# ATmega16A device description
Architecture: AVR8; Family: megaAVR
Registers are 8-bit, access not given, no defined reset value unless marked. A register's access mark holds for its fields unless they carry their own. Offsets are from the block's base; [hi:lo] are bit positions; 'fields as' and 'values as' point back to an identical list.

## LOCKBIT — Lockbits
Instances: LOCKBIT 0 in lockbits
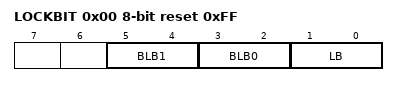
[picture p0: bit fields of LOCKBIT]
0x00 LOCKBIT reset 0xFF
  [5:4] BLB1 — Boot Loader Protection Mode
    0=LPM_SPM_DISABLE (LPM and SPM prohibited in Boot Section); 1=LPM_DISABLE (LPM prohibited in Boot Section); 2=SPM_DISABLE (SPM prohibited in Boot Section); 3=NO_LOCK (No lock on SPM and LPM in Boot Section)
  [3:2] BLB0 — Boot Loader Protection Mode
    0=LPM_SPM_DISABLE (LPM and SPM prohibited in Application Section); 1=LPM_DISABLE (LPM prohibited in Application Section); 2=SPM_DISABLE (SPM prohibited in Application Section); 3=NO_LOCK (No lock on SPM and LPM in Application Section)
  [1:0] LB — Memory Lock
    0=PROG_VER_DISABLED (Further programming and verification disabled); 2=PROG_DISABLED (Further programming disabled); 3=NO_LOCK (No memory lock features enabled)

## TC0 (TC8 module) — Timer/Counter, 8-bit
Instances: TC0 0x00
0x50 SFIOR — Special Function IO Register
  [0] PSR10 — Prescaler Reset Timer/Counter1 and Timer/Counter0
0x52 TCNT0 — Timer/Counter 0 Register
  [7:0] TCNT0 — Timer/Counter 0 bits
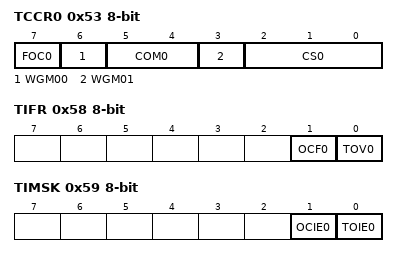
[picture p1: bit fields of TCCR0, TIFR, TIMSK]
0x53 TCCR0 — Timer/Counter Control Register
  [7] FOC0 — Force Output Compare
  [6] WGM00 — Waveform Generation Mode 0
    0=Normal; 2=PWM, Phase Correct; 1=CTC; 3=Fast PWM
  [5:4] COM0 — Compare Match Output Modes
  [3] WGM01 — Waveform Generation Mode 1
  [2:0] CS0 — Clock Selects
    0=No Clock Source (Stopped); 1=Running, No Prescaling; 2=Running, CLK/8; 3=Running, CLK/64; 4=Running, CLK/256; 5=Running, CLK/1024; 6=Running, ExtClk Tx Falling Edge; 7=Running, ExtClk Tx Rising Edge
0x58 TIFR — Timer/Counter Interrupt Flag register
  [1] OCF0 — Output Compare Flag 0
  [0] TOV0 — Timer/Counter0 Overflow Flag
0x59 TIMSK — Timer/Counter Interrupt Mask Register
  [1] OCIE0 — Timer/Counter0 Output Compare Match Interrupt register
  [0] TOIE0 — Timer/Counter0 Overflow Interrupt Enable
0x5C OCR0 — Output Compare 0 Register
  [7:0] OCR0 — Output Compare bits

## TC1 (TC16 module) — Timer/Counter, 16-bit
Instances: TC1 0x00
0x46 ICR1 16-bit — Timer/Counter1 Input Capture Register Bytes
  [15:0] ICR1 — Timer/Counter1 Input Capture bits
0x48 OCR1B 16-bit — Timer/Counter1 Output Compare Register Bytes
  [15:0] OCR1B — Timer/Counter1 Output Compare B bits
0x4A OCR1A 16-bit — Timer/Counter1 Output Compare Register Bytes
  [15:0] OCR1A — Timer/Counter1 Output Compare A bits
0x4C TCNT1 16-bit — Timer/Counter1 Bytes
  [15:0] TCNT1 — Timer/Counter1 bits
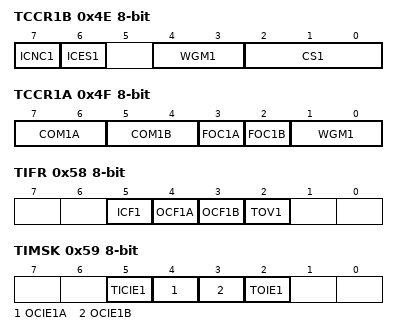
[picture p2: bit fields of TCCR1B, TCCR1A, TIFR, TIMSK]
0x4E TCCR1B — Timer/Counter1 Control Register B
  [7] ICNC1 — Input Capture 1 Noise Canceler
  [6] ICES1 — Input Capture 1 Edge Select
  [4:3] WGM1 (bit 2 of the value upward) — Waveform Generation Mode
  [2:0] CS1 — Prescaler source of Timer/Counter 1
    0=No Clock Source (Stopped); 1=Running, No Prescaling; 2=Running, CLK/8; 3=Running, CLK/64; 4=Running, CLK/256; 5=Running, CLK/1024; 6=Running, ExtClk Tx Falling Edge; 7=Running, ExtClk Tx Rising Edge
0x4F TCCR1A — Timer/Counter1 Control Register A
  [7:6] COM1A — Compare Output Mode 1A, bits
  [5:4] COM1B — Compare Output Mode 1B, bits
  [3] FOC1A — Force Output Compare 1A
  [2] FOC1B — Force Output Compare 1B
  [1:0] WGM1 — Waveform Generation Mode
0x58 TIFR — Timer/Counter Interrupt Flag register
  [5] ICF1 — Input Capture Flag 1
  [4] OCF1A — Output Compare Flag 1A
  [3] OCF1B — Output Compare Flag 1B
  [2] TOV1 — Timer/Counter1 Overflow Flag
0x59 TIMSK — Timer/Counter Interrupt Mask Register
  [5] TICIE1 — Timer/Counter1 Input Capture Interrupt Enable
  [4] OCIE1A — Timer/Counter1 Output CompareA Match Interrupt Enable
  [3] OCIE1B — Timer/Counter1 Output CompareB Match Interrupt Enable
  [2] TOIE1 — Timer/Counter1 Overflow Interrupt Enable

## EXINT — External Interrupts
Instances: EXINT 0x00
0x54 MCUCSR — MCU Control And Status Register
  [6] ISC2 — Interrupt Sense Control 2
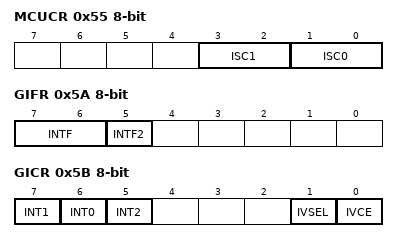
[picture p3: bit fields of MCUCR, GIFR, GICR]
0x55 MCUCR — General Interrupt Control Register
  [3:2] ISC1 — Interrupt Sense Control 1 Bits
    0=Low Level of INTX; 1=Any Logical Change of INTX; 2=Falling Edge of INTX; 3=Rising Edge of INTX
  [1:0] ISC0 — Interrupt Sense Control 0 Bits
    values as ISC1
0x5A GIFR — General Interrupt Flag Register
  [7:6] INTF — External Interrupt Flags
  [5] INTF2 — External Interrupt Flag 2
0x5B GICR — General Interrupt Control Register
  [7] INT1 — External Interrupt Request 1 Enable
  [6] INT0 — External Interrupt Request 0 Enable
  [5] INT2 — External Interrupt Request 2 Enable
  [1] IVSEL — Interrupt Vector Select
  [0] IVCE — Interrupt Vector Change Enable
